# RZN2L register map
Vendor: Renesas Electronics Corporation; Series: RZN; File version: 1.30.01
CPU: other r0p0, little endian, MPU, no FPU, VTOR, 4 interrupt priority bits, 624 interrupts
Registers are 32-bit, read-write, reset 0x0 unless marked. A register's access mark holds for its fields unless they carry their own. Offsets are from the block's base; [hi:lo] are bit positions; {n}, {i} and the like mark numbered series; 'fields as' and 'values as' point back to an identical list.

## PHOSTIF — Parallel Host Interface
Base 0x80242000
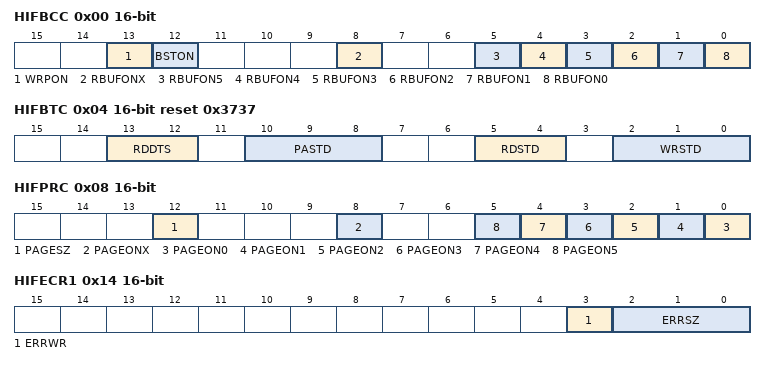
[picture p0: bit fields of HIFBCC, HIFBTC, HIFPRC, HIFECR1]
0x00 HIFBCC 16-bit — HOSTIF Bus Control Register
  [13] WRPON
    0=INCR4; 1=WRAP4
  [12] BSTON
    0=Single transfer is used; 1=Burst transfer is used
  [8] RBUFONX
    0=Read ahead function disabled; 1=Read ahead function disabled
  [5] RBUFON5
    0=Read-ahead function disabled; 1=Read-ahead function disabled
  [4] RBUFON4
    values as RBUFON5
  [3] RBUFON3
    0=Read-ahead function disabled; 1=Read-ahead function enabled
  [2] RBUFON2
    values as RBUFON3
  [1] RBUFON1
    values as RBUFON5
  [0] RBUFON0
    values as RBUFON3
0x04 HIFBTC 16-bit reset 0x3737 — HOSTIF Timing Control Register
  [13:12] RDDTS
    0=No wait; 1=Wait for 1 clock cycle of PCLKH; 2=Wait for 2 clock cycles of PCLKH; 3=Wait for 3 clock cycles of PCLKH
  [10:8] PASTD
    0=No wait; 1=Wait for 1 clock cycle of PCLKH; {v}=Wait for {v} clock cycles of PCLKH (v=2..7)
  [5:4] RDSTD — Specifies the timing for detecting the start of read operation by the HRD# signal.
    0=Simultaneous with the detection of the falling edge after synchronization; 1=Delay by 1 clock cycle of PCLKH from the detection of the falling edge after synchronization; 2=Delay by 2 clock cycles of PCLKH from the detection of the falling edge after synchronization; 3=Delay by 3 clock cycles of PCLKH from the detection of the falling edge after synchronization
  [2:0] WRSTD — Specifies the timing for detecting the start of write operation by the HWRSTB# signal.
    0=Simultaneous with the detection of the falling edge after synchronization; 1=Delay by 1 clock cycle of PCLKH from the detection of the falling edge after synchronization; {v}=Delay by {v} clock cycles of PCLKH from the detection of the falling edge after synchronization (v=2..7)
0x08 HIFPRC 16-bit — HOSTIF Page ROM Control Register
  [12] PAGESZ
    0=8-byte; 1=16-byte
  [8] PAGEONX
    0=SRAM reading; 1=Page ROM reading
  [n] PAGEON{n} (n=0..5)
    0=SRAM reading; 1=Page ROM reading
0x0C HIFIRC 16-bit — HOSTIF Interrupt Request Control Register
  [0] ERRRSP — This bit is set to 1 on reception of an error response from internal slave modules.
    0=No error response; 1=Error response
0x10 HIFECR0 ro — HOSTIF Error Source Register 0
  [31:0] ERRADDR
0x14 HIFECR1 16-bit ro — HOSTIF Error Source Register 1
  [3] ERRWR
    0=Reading; 1=Writing
  [2:0] ERRSZ
    0=8-bit; 1=16-bit; 2=32-bit; other=Others (Setting prohibited)
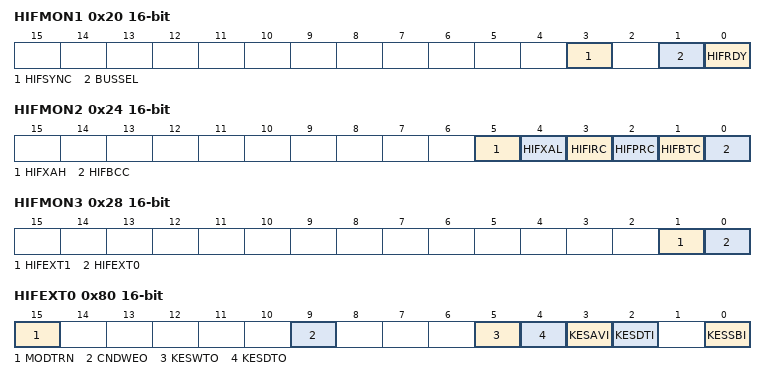
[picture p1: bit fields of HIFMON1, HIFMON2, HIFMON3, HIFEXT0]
0x20 HIFMON1 16-bit — HOSTIF Monitor Register 1
  [3] HIFSYNC ro
    0=Asynchronous mode; 1=Synchronous mode
  [1] BUSSEL ro
    0=8-bit bus width; 1=16-bit bus width
  [0] HIFRDY
    0=Internal initializing; 1=Internal initialization complete
0x24 HIFMON2 16-bit ro (reset mask 0xFFC0) — HOSTIF Monitor Register 2
  [all] fields
    0=Read only; 1=Read and Write
  [5] HIFXAH
  [4] HIFXAL
  [3] HIFIRC
  [2] HIFPRC
  [1] HIFBTC
  [0] HIFBCC
0x28 HIFMON3 16-bit ro (reset mask 0xFFFC) — HOSTIF Monitor Register 3
  [1] HIFEXT1
    0=Read only; 1=Read and Write
  [0] HIFEXT0
    0=Read only; 1=Read and Write
0x30 HIFXAL 16-bit — HOSTIF Specified Area Lower-limit Register
  [8:0] XADDRL — Specifies the lower-limit address of the specified area to be set in the external bus address space.
0x34 HIFXAH 16-bit — HOSTIF Specified Area Upper-limit Register
  [8:0] XADDRH — Specifies the upper-limit address of the specified area to be set in the external bus address space.
0x80 HIFEXT0 16-bit — HOSTIF Synchronous Burst Transfer Control Register 0
  [15] MODTRN
    0=Single transfer only; 1=Burst transfer is supported
  [9] CNDWEO
    0=Simultaneous with data; 1=Precedes the data by one clock cycle
  [5] KESWTO
    0=Rising edge; 1=Falling edge
  [4] KESDTO
    0=Rising edge; 1=Falling edge
  [3] KESAVI
    0=Rising edge; 1=Falling edge
  [2] KESDTI
    0=Rising edge; 1=Falling edge
  [0] KESSBI
    0=Rising edge; 1=Falling edge
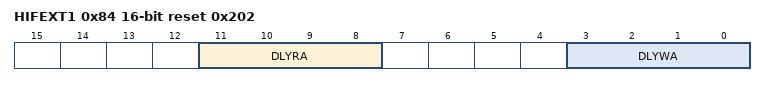
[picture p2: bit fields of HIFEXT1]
0x84 HIFEXT1 16-bit reset 0x202 — HOSTIF Synchronous Burst Transfer Control Register 1
  [11:8] DLYRA — Minimum time from the last input of the Low level on the HBS# pin to the point where read data can be acquired. (trc)DLYRA[3:0]CNDWEO = 0CNDWEO = 10x0450x1450x2550x3660x4770x5880x6990x710100x811110x912120xA13130xB14140xC15150xD16160xE17170xF1818
  [3:0] DLYWA — Minimum time from the last input of the Low level on the HBS# pin to the point where write data is received. (twc)DLYWA[3:0]CNDWEO = 0CNDWEO = 0HWRSTB# = 0HWRSTB# = 1HWRSTB# = 0HWRSTB# = 10x034450x134450x234450x344450x455550x566660x677770x788880x899990x9101010100xA111111110xB121212120xC131313130xD141414140xE151515150xF16161616
